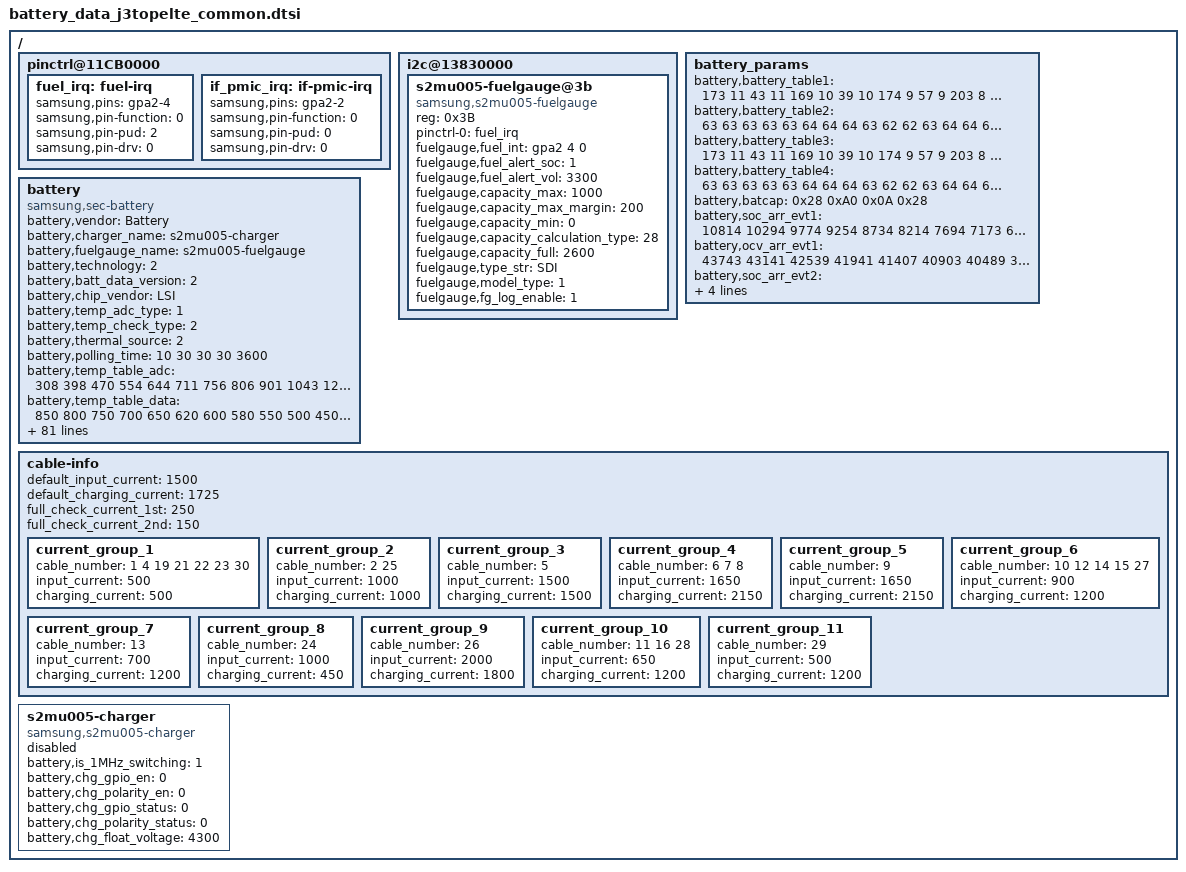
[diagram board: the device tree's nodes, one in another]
/*
 * J3 TOP Battery parameters device tree file for board IDs 04 and higher
 *
 * Copyright (C) 2017 Samsung Electronics, Inc.
 *
 * This program is free software; you can redistribute it and/or
 * modify it under the terms of the GNU General Public License
 * as published by the Free Software Foundation; either version 2
 * of the License, or (at your option) any later version.
 *
 * This program is distributed in the hope that it will be useful,
 * but WITHOUT ANY WARRANTY; without even the implied warranty of
 * MERCHANTABILITY or FITNESS FOR A PARTICULAR PURPOSE.  See the
 * GNU General Public License for more details.
 *
 * You should have received a copy of the GNU General Public License
 * along with this program. If not, see <http://www.gnu.org/licenses/>.
 *
 */

/ {
	pinctrl@11CB0000 {
		fuel_irq: fuel-irq {
			samsung,pins = "gpa2-4";
			samsung,pin-function = <0>;
			samsung,pin-pud = <2>;
			samsung,pin-drv = <0>;
		};

		if_pmic_irq: if-pmic-irq {
			samsung,pins = "gpa2-2";
			samsung,pin-function = <0>;
			samsung,pin-pud = <0>;
			samsung,pin-drv = <0>;
		};
	};

	i2c@13830000 {
		status = "okay";
		s2mu005-fuelgauge@3b {
			compatible = "samsung,s2mu005-fuelgauge";
			reg = <0x3B>;
			pinctrl-names = "default";
			pinctrl-0 = <&fuel_irq>;
			fuelgauge,fuel_int = <&gpa2 4 0>;
			fuelgauge,fuel_alert_soc = <1>;
			fuelgauge,fuel_alert_vol = <3300>;
			fuelgauge,capacity_max = <1000>;
			fuelgauge,capacity_max_margin = <200>;
			fuelgauge,capacity_min = <0>;
			fuelgauge,capacity_calculation_type = <28>;
			fuelgauge,capacity_full = <2600>;
			fuelgauge,type_str = "SDI";
			fuelgauge,model_type = <1>;
			fuelgauge,fg_log_enable = <1>;
		};
	};

	battery_params {
			battery,battery_table1 = <
					173 11 43 11 169 10 39 10 174 9
					57 9 203 8 101 8 0 8 169 7
					58 7 230 6 175 6 132 6 98 6
					68 6 34 6 245 5 192 5 137 5
					243 4 128 1 18 9 162 8 50 8
					194 7 81 7 225 6 113 6 1 6
					145 5 32 5 176 4 64 4 208 3
					95 3 239 2 127 2 15 2 158 1
					46 1 190 0 78 0 222 15
					>;

			battery,battery_table2 = <
					63 63 63 63 63 64 64 64 63 62
					62 63 64 64 65 65 66 68 71 81
					104 233
					>;

			battery,battery_table3 = <
					173 11 43 11 169 10 39 10 174 9
					57 9 203 8 101 8 0 8 169 7
					58 7 230 6 175 6 132 6 98 6
					68 6 34 6 245 5 192 5 137 5
					243 4 128 1 18 9 162 8 50 8
					194 7 81 7 225 6 113 6 1 6
					145 5 32 5 176 4 64 4 208 3
					95 3 239 2 127 2 15 2 158 1
					46 1 190 0 78 0 222 15
					>;

			battery,battery_table4 = <
					63 63 63 63 63 64 64 64 63 62
					62 63 64 64 65 65 66 68 71 81
					104 233
					>;

			battery,batcap = <0x28 0xA0 0x0A 0x28>; /* [0x0F] [0x0E] [0x11] [0x10] */

			battery,soc_arr_evt1 = <
						10814 10294 9774 9254 8734 8214 7694 7173 6653 6133
						5613 5093 4573 4053 3533 3013 2493 1971 1452 932
						412 (-108)
						>;
			battery,ocv_arr_evt1 = <
						43743 43141 42539 41941 41407 40903 40489 39813 39576 39229
						38818 38397 38161 37995 37867 37775 37692 37508 37195 36925
						36300 32467
						>;

			battery,soc_arr_evt2 = <
						10814 10294 9774 9254 8734 8214 7694 7173 6653 6133
						5613 5093 4573 4053 3533 3013 2493 1971 1452 932
						412 (-108)
						>;
			battery,ocv_arr_evt2 = <
						43743 43141 42539 41941 41407 40903 40489 39813 39576 39229
						38818 38397 38161 37995 37867 37775 37692 37508 37195 36925
						36300 32467
						>;

			battery,FG_Accumulative_rate_evt2 = <0x00 0x8>; /* 0x44 0x45 */
	};

	battery {
		status = "okay";
		compatible = "samsung,sec-battery";

		pinctrl-names = "default";

		battery,vendor = "Battery";
		battery,charger_name = "s2mu005-charger";
		battery,fuelgauge_name = "s2mu005-fuelgauge";
		battery,technology = <2>; /* POWER_SUPPLY_TECHNOLOGY_LION */

		battery,batt_data_version = <2>;

		battery,chip_vendor = "LSI";
		battery,temp_adc_type = <1>; /* SEC_BATTERY_ADC_TYPE_AP */

		battery,temp_check_type = <2>; /* SEC_BATTERY_TEMP_CHECK_TEMP */

		battery,thermal_source = <2>; /* SEC_BATTERY_THERMAL_SOURCE_ADC */

		battery,polling_time = <10 30 30 30 3600>;

		battery,temp_table_adc = <
					308 398 470 554 644 711 756 806 901 1043
					1200 1308 1385 1461 1586 1806 2043 2274 2440 2613
					2723 2875 2937 3126 3288 3470 3540 3677
					>;
		battery,temp_table_data = <
					850 800 750 700 650 620 600 580 550 500 450
					420 400 380 350 300 250 200 150 120 100
					80 50 0 (-50) (-100) (-150) (-200)
					>;

		battery,adc_check_count = <5>;

		battery,cable_check_type = <4>; /* SEC_BATTERY_CABLE_CHECK_PSY */
		battery,cable_source_type = <1>; /* SEC_BATTERY_CABLE_SOURCE_EXTERNAL */
		battery,polling_type = <1>; /* SEC_BATTERY_MONITOR_ALARM */
		battery,monitor_initial_count = <0>;

		battery,pre_afc_input_current = <500>;

		battery,battery_check_type = <5>; /* SEC_BATTERY_CHECK_CHARGER */
		battery,check_count = <0>;

		battery,ovp_uvlo_check_type = <3>; /* SEC_BATTERY_OVP_UVLO_CHGPOLLING */

		battery,temp_check_count = <1>;
		battery,temp_highlimit_threshold_event = <800>;
		battery,temp_highlimit_recovery_event = <750>;
		battery,temp_high_threshold_event = <500>;
		battery,temp_high_recovery_event = <450>;
		battery,temp_low_threshold_event = <0>;
		battery,temp_low_recovery_event = <50>;
		battery,temp_highlimit_threshold_normal = <800>;
		battery,temp_highlimit_recovery_normal = <750>;
		battery,temp_high_threshold_normal = <500>;
		battery,temp_high_recovery_normal = <450>;
		battery,temp_low_threshold_normal = <0>;
		battery,temp_low_recovery_normal = <50>;
		battery,temp_highlimit_threshold_lpm = <800>;
		battery,temp_highlimit_recovery_lpm = <750>;
		battery,temp_high_threshold_lpm = <500>;
		battery,temp_high_recovery_lpm = <450>;
		battery,temp_low_threshold_lpm = <0>;
		battery,temp_low_recovery_lpm = <50>;
		battery,wpc_high_threshold_normal = <450>;
		battery,wpc_high_recovery_normal = <400>;
		battery,wpc_low_threshold_normal = <0>;
		battery,wpc_low_recovery_normal = <50>;

		battery,full_check_type = <2>; /* SEC_BATTERY_FULLCHARGED_FG_CURRENT */
		battery,full_check_type_2nd = <2>; /* SEC_BATTERY_FULLCHARGED_FG_CURRENT */
		battery,full_check_count = <1>;
		battery,chg_gpio_full_check = <0>;
		battery,chg_polarity_full_check = <1>;

		/* SEC_BATTERY_FULL_CONDITION_SOC |
		   SEC_BATTERY_FULL_CONDITION_NOTIMEFULL |
		   SEC_BATTERY_FULL_CONDITION_VCELL */
		battery,full_condition_type = <13>;
		battery,full_condition_soc = <93>;
		battery,full_condition_vcell = <4200>;

		battery,recharge_check_count = <1>;
		battery,recharge_condition_type = <4>; /* SEC_BATTERY_RECHARGE_CONDITION_VCELL */
		battery,recharge_condition_soc = <98>;
		battery,recharge_condition_vcell = <4230>;

		battery,charging_total_time = <14400>;
		battery,hv_charging_total_time = <10800>;
		battery,normal_charging_total_time = <18000>;
		battery,usb_charging_total_time = <36000>;
		battery,recharging_total_time = <5400>;
		battery,charging_reset_time = <0>;

		battery,chg_float_voltage = <4300>;

		battery,swelling_high_temp_block = <410>;
		battery,swelling_high_temp_recov = <390>;
		battery,swelling_wc_high_temp_recov = <390>;
		battery,swelling_low_temp_block_1st = <150>;
		battery,swelling_low_temp_recov_1st = <200>;
		battery,swelling_low_temp_block_2nd = <50>;
		battery,swelling_low_temp_recov_2nd = <100>;

		battery,swelling_low_temp_current = <600>;	/* 0.3C */
		battery,swelling_low_temp_topoff = <150>;	/* 0.05C */
		battery,swelling_high_temp_current = <900>;	/* 0.45C */
		battery,swelling_high_temp_topoff = <150>;	/* 0.05C */
		battery,swelling_wc_high_temp_current = <700>;	/* 0.3C */
		battery,swelling_wc_low_temp_current = <700>;	/* 0.3C */

		battery,swelling_drop_float_voltage = <4100>;
		battery,swelling_high_rechg_voltage = <3950>;
		battery,swelling_low_rechg_voltage = <3950>;

		battery,siop_event_check_type = <1>;
		battery,siop_call_cv_current = <330>;
		battery,siop_call_cc_current = <330>;

		battery,siop_input_limit_current = <1200>;
		battery,siop_charging_limit_current = <1000>;

		battery,battery_full_capacity = <2600>;

		/* cycle, chg_float_voltage, recharge_condition_vcell, full_condition_vcell, full_condition_soc */
		battery,age_data = <0 4300 4230 4200 93	/*4.35*/
				200 4280 4210 4180 92	/*4.33*/
				250 4260 4190 4160 91	/*4.31*/
				300 4240 4170 4140 90	/*4.29*/
				1000 4220 4150 4120 89	/*4.24*/
				>;

		battery,standard_curr = <1725>;
		battery,expired_time = <18000>; /* 300 minutes */
		battery,recharging_expired_time = <5400>;

		battery,cisd_max_voltage_thr = <4350>; /* battery ovp detection voltage */

		io-channels = <&exynos_adc 1>;
		io-channel-names = "adc-temp";
		#io-channel-cells = <5>;
		io-channel-ranges;

	};

/* sec_battery_cable
 *   0	UNKNOWN,
 *   1	NONE,
 *   2	PREPARE_TA,
 *   3	TA,
 *   4	USB,
 *   5	USB_CDP,
 *   6	9V_TA,
 *   7	9V_ERR,
 *   8	9V_UNKNOWN,
 *   9	12V_TA,
 *  10	WIRELESS,
 *  11	HV_WIRELESS,
 *  12	PMA_WIRELESS,
 *  13	WIRELESS_PACK,
 *  14	WIRELESS_PACK_TA,
 *  15	WIRELESS_STAND,
 *  16	WIRELESS_HV_STAND,
 *  17	QC20,
 *  18	QC30,
 *  19	PDIC,
 *  20	UARTOFF,
 *  21	OTG,
 *  22	LAN_HUB,
 *  23	POWER_SHARING,
 *  24	HMT_CONNECTED,
 *  25	HMT_CHARGE,
 *  26	HV_TA_CHG_LIMIT,
 *  27	WIRELESS_VEHICLE,
 *  28	WIRELESS_HV_VEHICLE,
 *  29	PREPARE_WIRELESS_HV,
 *  30	TIMEOUT,
 *  31	CABLE_MAX,
*/
	cable-info {
		   default_input_current = <1500>;
		   default_charging_current = <1725>;
		   full_check_current_1st = <250>;
		   full_check_current_2nd = <150>;

		   current_group_1 {
		   	       cable_number = <1 4 19 21 22 23 30>;
			       input_current = <500>;
			       charging_current = <500>;
		   };
		   current_group_2 {
		   	       cable_number = <2 25>;
			       input_current = <1000>;
			       charging_current = <1000>;
		  };
		   current_group_3 {
		   	       cable_number = <5>;
			       input_current = <1500>;
			       charging_current = <1500>;
		  };
		   current_group_4 {
		   	       cable_number = <6 7 8>;
			       input_current = <1650>;
			       charging_current = <2150>;
		  };
		   current_group_5 {
		   	       cable_number = <9>;
			       input_current = <1650>;
			       charging_current = <2150>;
		  };
		   current_group_6 {
		   	       cable_number = <10 12 14 15 27>;
			       input_current = <900>;
			       charging_current = <1200>;
		  };
		   current_group_7 {
		   	       cable_number = <13>;
			       input_current = <700>;
			       charging_current = <1200>;
		  };
		   current_group_8 {
		   	       cable_number = <24>;
			       input_current = <1000>;
			       charging_current = <450>;
		  };
		   current_group_9 {
		   	       cable_number = <26>;
			       input_current = <2000>;
			       charging_current = <1800>;
		  };
		   current_group_10 {
		   	       cable_number = <11 16 28>;
			       input_current = <650>;
			       charging_current = <1200>;
		  };
		   current_group_11 {
		   	       cable_number = <29>;
			       input_current = <500>;
			       charging_current = <1200>;
		  };
	};

	s2mu005-charger {
		status = "disable";
		compatible = "samsung,s2mu005-charger";
		battery,is_1MHz_switching = <1>;
		battery,chg_gpio_en = <0>;
		battery,chg_polarity_en = <0>;
		battery,chg_gpio_status = <0>;
		battery,chg_polarity_status = <0>;
		battery,chg_float_voltage = <4300>;
	};
};
